# ATSAMRH71F20C register map
Vendor: Microchip Technology; Series: SAMRH71; File version: 0
CPU: CM7 r1p1, little endian, MPU, FPU, 3 interrupt priority bits
Registers are 32-bit, read-write, reset 0x0 unless marked. A register's access mark holds for its fields unless they carry their own. Offsets are from the block's base; [hi:lo] are bit positions; {n}, {i} and the like mark numbered series; 'fields as' and 'values as' point back to an identical list.

## FLEXRAMECC
Base 0x40100600; register names take the prefix FLEXRAMECC_
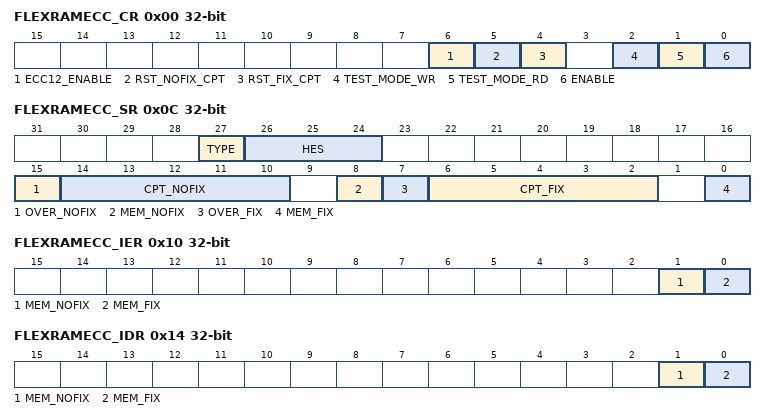
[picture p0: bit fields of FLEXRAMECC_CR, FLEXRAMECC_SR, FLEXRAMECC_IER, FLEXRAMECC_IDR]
0x00 FLEXRAMECC_CR — FLEXRAMECC Control Register
  [6] ECC12_ENABLE — BCH ECC enable
  [5] RST_NOFIX_CPT — reset the un-fixable error counter
  [4] RST_FIX_CPT — reset the fixable error counter
  [2] TEST_MODE_WR — test mode of ECC protection - write mode
  [1] TEST_MODE_RD — test mode of ECC protection - read mode
  [0] ENABLE — ECC protection enable
0x04 FLEXRAMECC_TESTCB1 — FLEXRAMECC Test mode register 1
  [7:0] TCB1 — Test Check Bit
0x0C FLEXRAMECC_SR ro — FLEXRAMECC Status register
  [27] TYPE — write or read access
  [26:24] HES — Hardware Error Size
  [15] OVER_NOFIX — counter overflow
  [14:10] CPT_NOFIX — 5 bits counter
  [8] MEM_NOFIX — Un-fixable error status
  [7] OVER_FIX — counter overflow
  [6:2] CPT_FIX — 5 bits counter
  [0] MEM_FIX — Fixable error status
0x10 FLEXRAMECC_IER wo — FLEXRAMECC Interrupt Enable Register
  [1] MEM_NOFIX — Un-fixable error
  [0] MEM_FIX — Fixable error
0x14 FLEXRAMECC_IDR wo — FLEXRAMECC Interrupt Disable Register
  [1] MEM_NOFIX — un-fixable error
  [0] MEM_FIX — fixable error
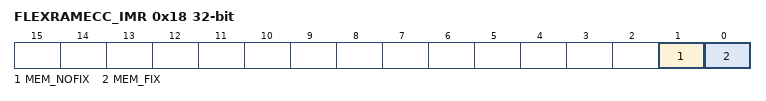
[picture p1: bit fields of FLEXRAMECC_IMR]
0x18 FLEXRAMECC_IMR ro — FLEXRAMECC Interrupt Mask Register
  [1] MEM_NOFIX — un-fixable error
  [0] MEM_FIX — fixable error
0x1C FLEXRAMECC_FAILAR ro — FLEXRAMECC Fail address register
  [31:0] ADDRESS — address of the error detected

## HSMC — Harden Static Memory Controller
Base 0x40081000; register names take the prefix HSMC_
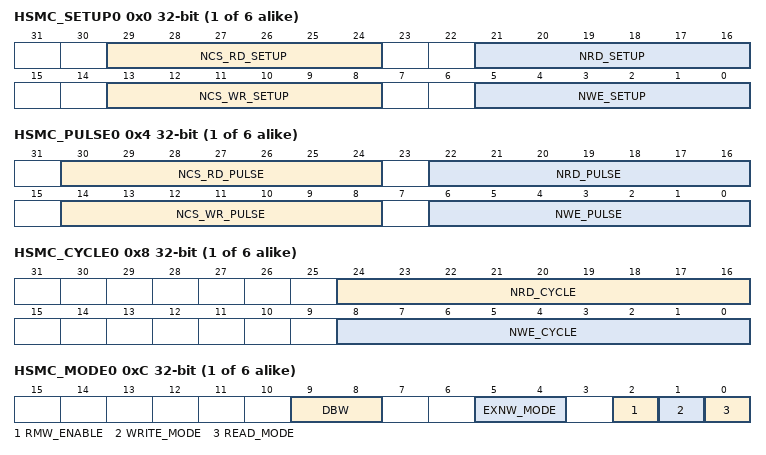
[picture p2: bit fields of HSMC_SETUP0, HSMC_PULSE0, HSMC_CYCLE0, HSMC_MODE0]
{0x0+0x10*i} HSMC_SETUP{i} (i=0..5) — HSMC Setup Register (CS_number = {i})
  [29:24] NCS_RD_SETUP — NCS Setup Length in READ Access
  [21:16] NRD_SETUP — NRD Setup Length
  [13:8] NCS_WR_SETUP — NCS Setup Length in WRITE Access
  [5:0] NWE_SETUP — NWE Setup Length
{0x4+0x10*i} HSMC_PULSE{i} (i=0..5) — HSMC Pulse Register (CS_number = {i})
  [30:24] NCS_RD_PULSE — NCS Pulse Length in READ Access
  [22:16] NRD_PULSE — NRD Pulse Length
  [14:8] NCS_WR_PULSE — NCS Pulse Length in WRITE Access
  [6:0] NWE_PULSE — NWE Pulse Length
{0x8+0x10*i} HSMC_CYCLE{i} (i=0..5) — HSMC Cycle Register (CS_number = {i})
  [24:16] NRD_CYCLE — Total Read Cycle Length
  [8:0] NWE_CYCLE — Total Write Cycle Length
{0xC+0x10*i} HSMC_MODE{i} (i=0..5) — HSMC Mode Register (CS_number = {i})
  [9:8] DBW — Data Bus Width
    0=_8_BIT (8-bit Data Bus); 1=_16_BIT (16-bit Data Bus); 2=_32_BIT (32-bit Data Bus)
  [5:4] EXNW_MODE — NWAIT Mode
    0=DISABLED (Disabled-The NWAIT input signal is ignored on the corresponding chip select.); 2=FROZEN (Frozen Mode-If asserted, the NWAIT signal freezes the current read or write cycle. After deassertion, the read/write cycle is resumed from the point where it was stopped.); 3=READY (Ready Mode-The NWAIT signal indicates the availability of the external device at the end of the pulse of the controlling read or write signal, to complete the access. If high, the access normally completes. If low, the access is extended until NWAIT returns high.)
  [2] RMW_ENABLE — Read-Modify Write enable
  [1] WRITE_MODE
  [0] READ_MODE
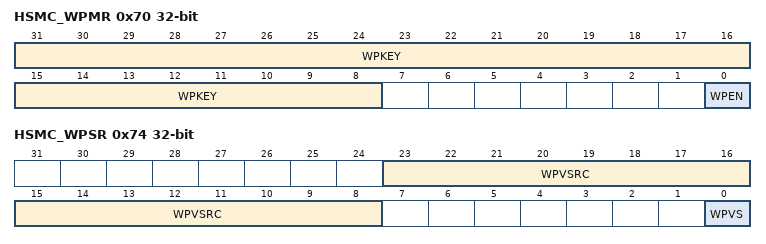
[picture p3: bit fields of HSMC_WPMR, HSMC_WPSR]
0x70 HSMC_WPMR — HSMC Write Protection Mode Register
  [31:8] WPKEY — Write Protection Key
    0x534D43=PASSWD (Writing any other value in this field aborts the write operation of the WPEN bit. Always reads as 0.)
  [0] WPEN — Write Protect Enable
0x74 HSMC_WPSR ro — HSMC Write Protection Status Register
  [23:8] WPVSRC — Write Protection Violation Source
  [0] WPVS — Write Protection Violation Status

## IP1553
Base 0x4003C000; register names take the prefix IP1553_
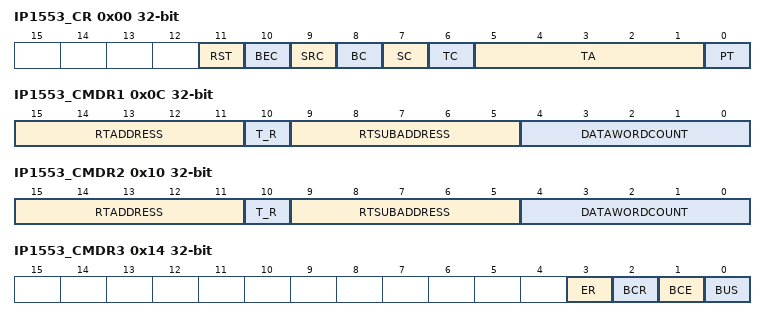
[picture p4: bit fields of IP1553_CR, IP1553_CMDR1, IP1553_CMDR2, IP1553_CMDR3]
0x00 IP1553_CR — Configuration Register
  [11] RST — Soft Reset
  [10] BEC — BCEnableCmd
  [9] SRC — SREQBitCmd
  [8] BC — BusyBitCmd
  [7] SC — SSBitCmd
  [6] TC — TRBitCmd
  [5:1] TA — TermAddressConf
  [0] PT — POTermConf
0x0C IP1553_CMDR1 wo — Command Register 1
  [15:11] RTADDRESS, [10] T_R, [9:5] RTSUBADDRESS, [4:0] DATAWORDCOUNT
0x10 IP1553_CMDR2 wo — Command Register 2
  [15:11] RTADDRESS
  [10] T_R — R/T
  [9:5] RTSUBADDRESS
  [4:0] DATAWORDCOUNT
0x14 IP1553_CMDR3 wo — Command Register 3
  [3] ER — data or command transfer
  [2] BCR — 1553 receiver
  [1] BCE — 1553 emitter
  [0] BUS — bus used
0x18 IP1553_BITR wo — BIT Register
  [15:0] TOBITWORD
0x1C IP1553_VWR wo — Vector Word Register
  [15:0] TOVECTORWORD
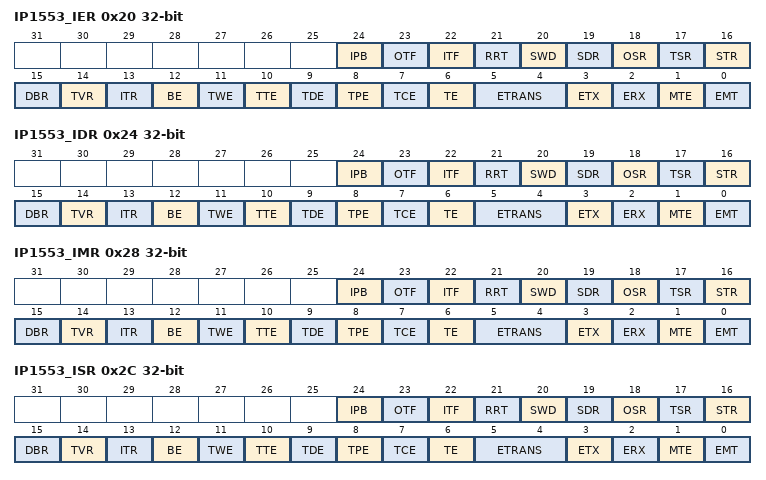
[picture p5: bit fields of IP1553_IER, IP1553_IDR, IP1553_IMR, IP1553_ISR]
0x20 IP1553_IER wo — IRQ Mask Enable Register
  [24] IPB — IPBusy
  [23] OTF — OvInhibitTermFlagReq
  [22] ITF — InhibitTermFlagReq
  [21] RRT — ResetRTReq
  [20] SWD — SyncWithoutDataReq
  [19] SDR — SyncWithDataReq
  [18] OSR — OvTranShutdownReq
  [17] TSR — TranShutdownReq
  [16] STR — InitSelfTestReq
  [15] DBR — DynamicBusContReq
  [14] TVR — TransVecWordReq
  [13] ITR — IllegalTransferReq
  [12] BE — BufIFErr
  [11] TWE — TransWordCounterErr
  [10] TTE — TransTimeOutErr
  [9] TDE — TransDataTypeErr
  [8] TPE — TransParityErr
  [7] TCE — TransCodingErr
  [6] TE — TransErr
  [5:4] ETRANS — EndTransfer
  [3] ETX — EndTransmission
  [2] ERX — End reception
  [1] MTE — MemTransferErr
  [0] EMT — EndMemTransfer
0x24 IP1553_IDR wo — IRQ Mask Disable Register
  fields as IP1553_IER
0x28 IP1553_IMR ro — IRQ Mask Register
  fields as IP1553_IER
0x2C IP1553_ISR ro — IRQ Status Register
  fields as IP1553_IER
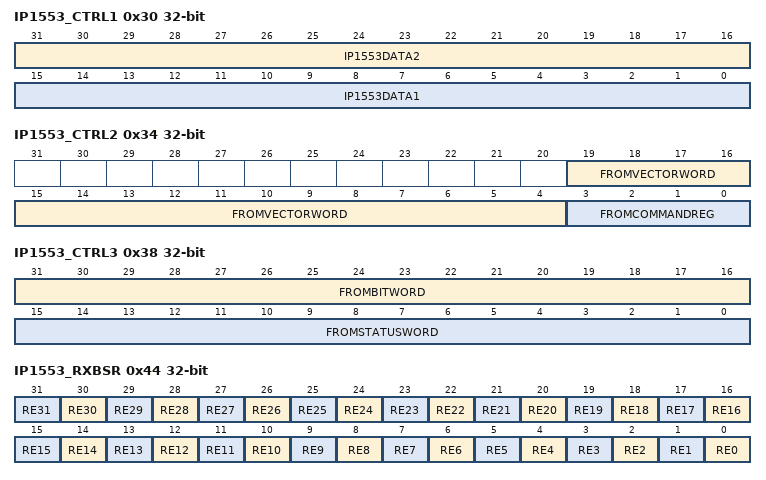
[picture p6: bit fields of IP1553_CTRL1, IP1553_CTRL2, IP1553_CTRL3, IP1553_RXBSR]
0x30 IP1553_CTRL1 ro — Control Register 1
  [31:16] IP1553DATA2 — IP1553 data value 2
  [15:0] IP1553DATA1 — IP1553 data value 1
0x34 IP1553_CTRL2 ro — Control Register 2
  [19:4] FROMVECTORWORD — from vector register
  [3:0] FROMCOMMANDREG — from command register
0x38 IP1553_CTRL3 ro — Control Register 3
  [31:16] FROMBITWORD — content of bit word register
  [15:0] FROMSTATUSWORD — content of status word register
0x3C IP1553_ARW — Address Register Write
  [31:0] REG_ADDR_APB_W — TX base address
0x40 IP1553_ARR — Address Register Read
  [31:0] REG_ADDR_APB_R — RX base address
0x44 IP1553_RXBSR — Rx Buffer Status Register
  [n] RE{n} (n=0..31) — Receive Buffer, {n} with x=[0-31]
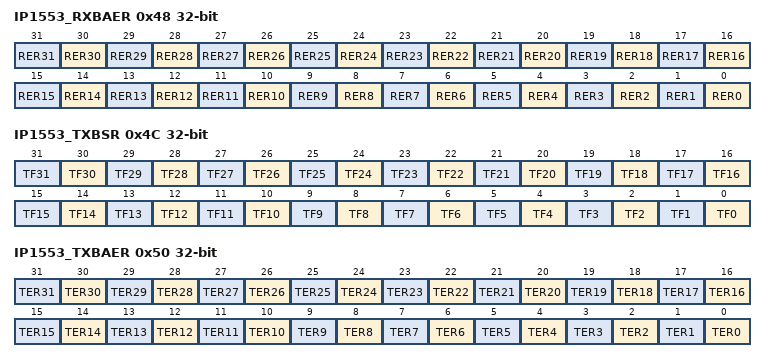
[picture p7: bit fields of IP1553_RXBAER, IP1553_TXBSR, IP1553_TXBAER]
0x48 IP1553_RXBAER — Rx Buffer Access Error Register
  [n] RER{n} (n=0..31) — Receive error {n}, x with x=[0-31]
0x4C IP1553_TXBSR — Tx Buffer Status Register
  [n] TF{n} (n=0..31) — Transmit buffer {n}, x with x=[0-31]
0x50 IP1553_TXBAER — Tx Buffer Access Error Register
  [n] TER{n} (n=0..31) — Transmit error {n}, x with x=[0-31]

## Notices in the file
Copyright (c) 2017 Microchip Technology Inc.
SPDX-License-Identifier: Apache-2.0
Licensed under the Apache License, Version 2.0 (the "License");
you may not use this file except in compliance with the License.
You may obtain a copy of the License at
http://www.apache.org/licenses/LICENSE-2.0
Unless required by applicable law or agreed to in writing, software
distributed under the License is distributed on an "AS IS" BASIS,
WITHOUT WARRANTIES OR CONDITIONS OF ANY KIND, either express or implied.
See the License for the specific language governing permissions and
limitations under the License.
